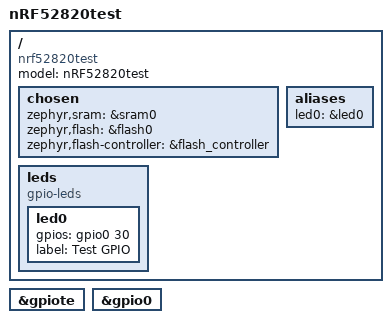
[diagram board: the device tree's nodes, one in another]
/dts-v1/;
#include <nordic/nrf52820_qdaa.dtsi>

/ {
  model = "nRF52820test";
  compatible = "nrf52820test";

  chosen {
    zephyr,sram = &sram0;
    zephyr,flash = &flash0;
    zephyr,flash-controller = &flash_controller;
  };

  leds {
	compatible = "gpio-leds";
	led0: led0 {
		gpios = <&gpio0 30 0>;
		label = "Test GPIO";
	};
   };

   aliases {
	led0 = &led0;
   };

};

&gpiote {
	status = "okay";
};

&gpio0 {
	status = "okay";
};
